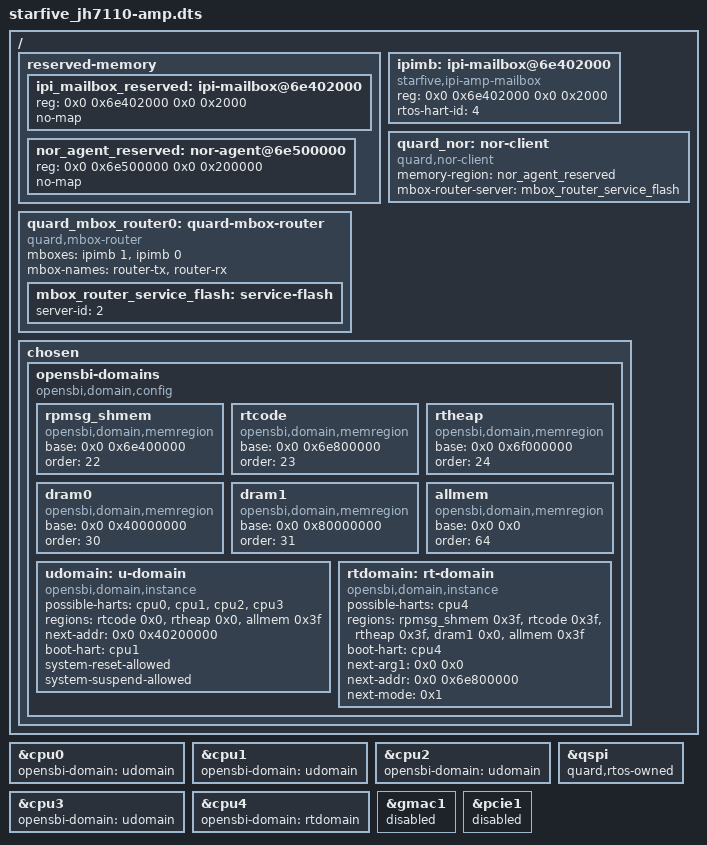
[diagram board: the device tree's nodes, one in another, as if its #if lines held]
// SPDX-License-Identifier: GPL-2.0 OR MIT
/*
 * Copyright (C) 2022 StarFive Technology Co., Ltd.
 */

/dts-v1/;
#if defined(CONFIG_TARGET_STARFIVE_VISIONFIVE2)
#include "starfive_visionfive2.dts"
#endif
#if defined(CONFIG_TARGET_STARFIVE_DEVKITS)
#include "starfive_devkits.dts"
#endif

/ {
	reserved-memory {
		#address-cells = <2>;
		#size-cells = <2>;
		ranges;

		ipi_mailbox_reserved: ipi-mailbox@6e402000 {
			reg = <0x0 0x6e402000 0x0 0x2000>;
			no-map;
		};

		nor_agent_reserved: nor-agent@6e500000 {
			reg = <0x0 0x6e500000 0x0 0x200000>;
			no-map;
		};
	};

	ipimb: ipi-mailbox@6e402000 {
		compatible = "starfive,ipi-amp-mailbox";
		reg = <0x0 0x6e402000 0x0 0x2000>;
		#mbox-cells = <1>;
		rtos-hart-id = <4>;
		status = "okay";
	};

	quard_mbox_router0: quard-mbox-router {
		compatible = "quard,mbox-router";
		mboxes = <&ipimb 1>, <&ipimb 0>;
		mbox-names = "router-tx", "router-rx";
		status = "okay";

		mbox_router_service_flash: service-flash {
			server-id = <2>;
		};
	};

	quard_nor: nor-client {
		compatible = "quard,nor-client";
		memory-region = <&nor_agent_reserved>;
		mbox-router-server = <&mbox_router_service_flash>;
		status = "okay";
	};

	chosen {
		opensbi-domains {
			compatible = "opensbi,domain,config";

			rpmsg_shmem: rpmsg_shmem {
				compatible = "opensbi,domain,memregion";
				base = <0x0 0x6e400000>;
				order = <22>;
			};

			rtcode: rtcode {
				compatible = "opensbi,domain,memregion";
				base = <0x0 0x6e800000>;
				order = <23>;
			};

			rtheap: rtheap {
				compatible = "opensbi,domain,memregion";
				base = <0x0 0x6f000000>;
				order = <24>;
			};

			dram0: dram0 {
				compatible = "opensbi,domain,memregion";
				base = <0x0 0x40000000>;
				order = <30>;
			};

			dram1: dram1 {
				compatible = "opensbi,domain,memregion";
				base = <0x0 0x80000000>;
				order = <31>;
			};

			allmem: allmem {
				compatible = "opensbi,domain,memregion";
				base = <0x0 0x0>;
				order = <64>;
			};

			udomain: u-domain {
				compatible = "opensbi,domain,instance";
				possible-harts = <&cpu0 &cpu1 &cpu2 &cpu3>;
				regions = <&rtcode 0x0>, <&rtheap 0x0>, <&allmem 0x3f>;
				next-addr = <0x0 0x40200000>;
				boot-hart = <&cpu1>;
				system-reset-allowed;
				system-suspend-allowed;
			};

			rtdomain: rt-domain {
				compatible = "opensbi,domain,instance";
				possible-harts = <&cpu4>;
				regions = <&rpmsg_shmem 0x3f>, <&rtcode 0x3f>, <&rtheap 0x3f>,
					<&dram1 0x0>, <&allmem 0x3f>;
				boot-hart = <&cpu4>;
				next-arg1 = <0x0 0x0>;
				next-addr = <0x0 0x6e800000>;
				next-mode = <0x1>;
			};
		};
	};
};

&cpu0 {
	opensbi-domain = <&udomain>;
};

&cpu1 {
	opensbi-domain = <&udomain>;
};

&cpu2 {
	opensbi-domain = <&udomain>;
};

&cpu3 {
	opensbi-domain = <&udomain>;
};

&cpu4 {
	opensbi-domain = <&rtdomain>;
};

/*
 * SPL still reads the boot payload through the physical Cadence QSPI
 * controller.  Before U-Boot proper scans driver model, board_fix_fdt()
 * sees this ownership marker and disables this controller in its writable
 * DT copy.  U-Boot proper must use quard_nor through the IPI router instead.
 */
&qspi {
	quard,rtos-owned;
};

&gmac1 {
	status = "disabled";
};

&pcie1 {
	status = "disabled";
};
